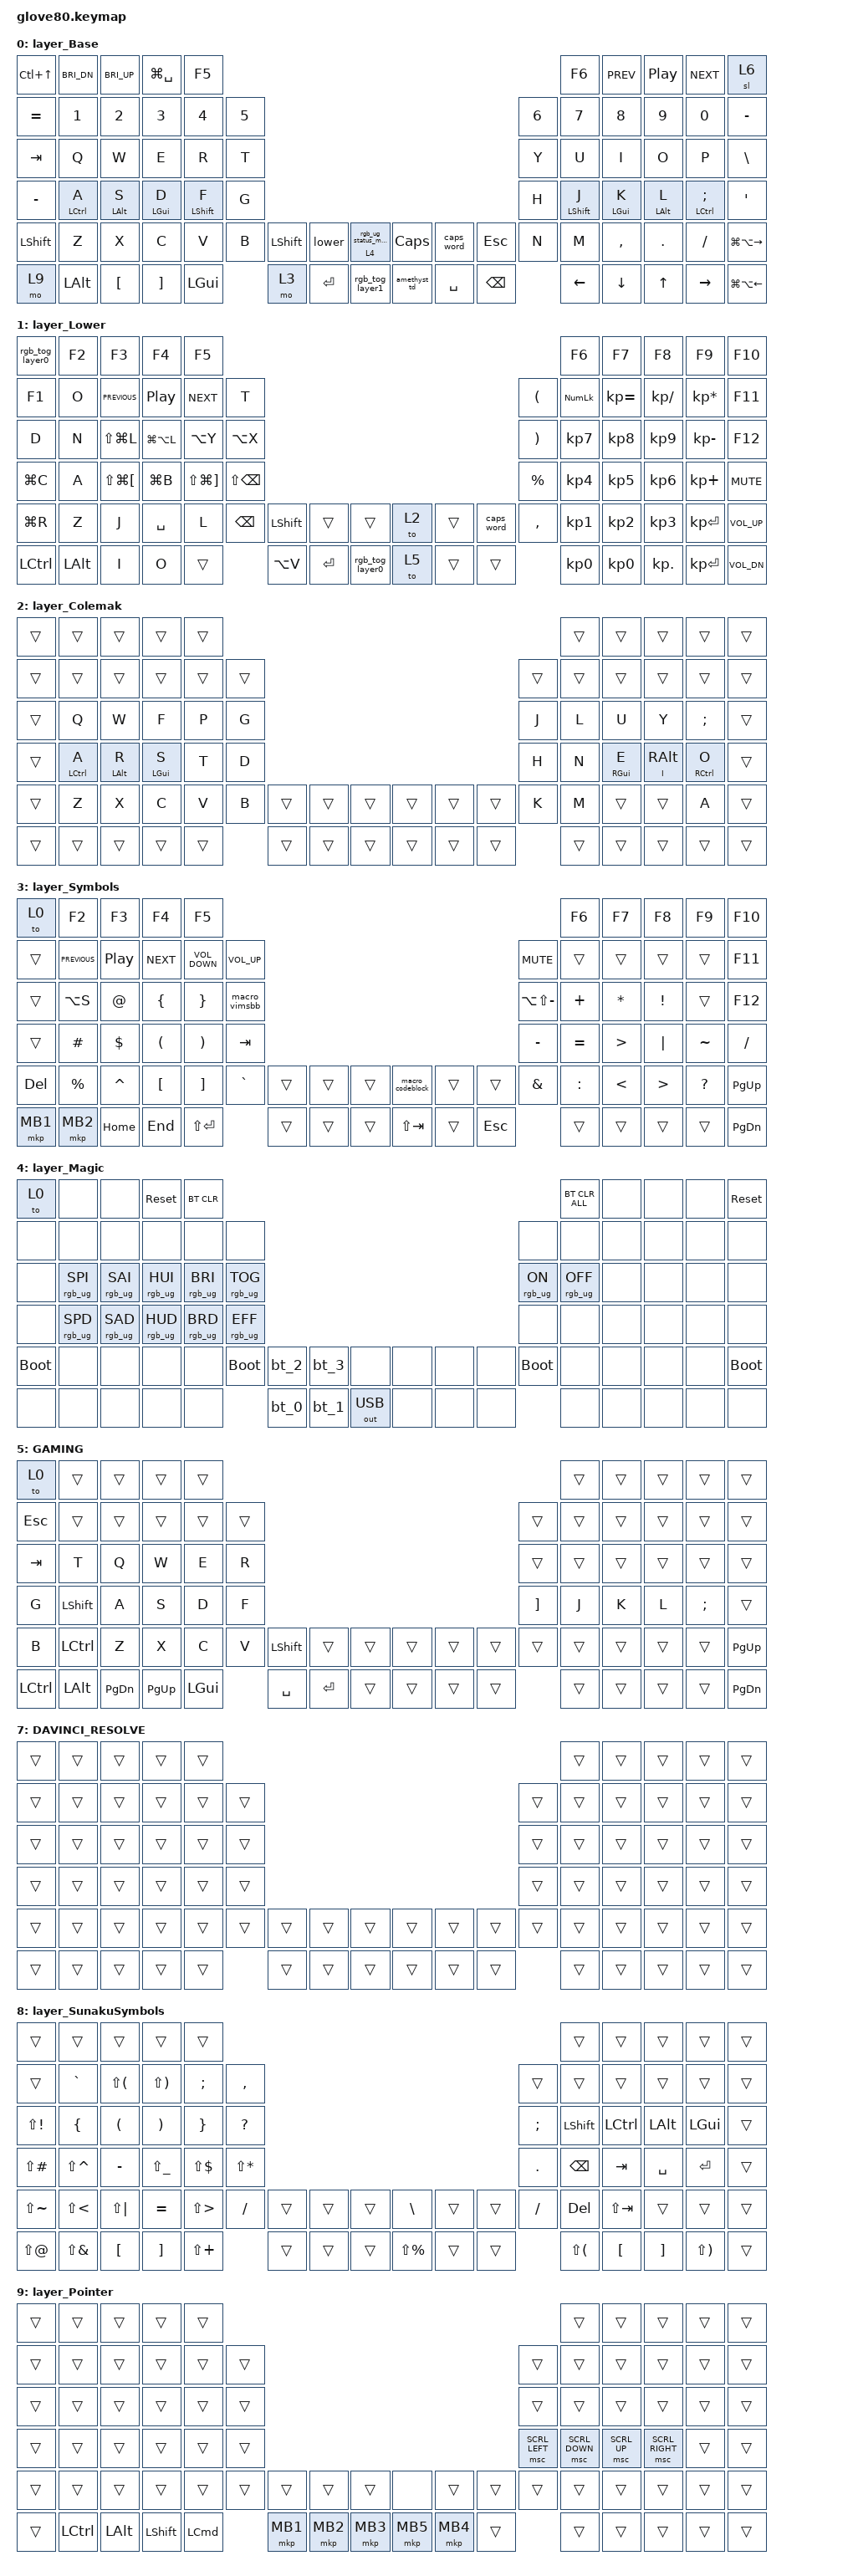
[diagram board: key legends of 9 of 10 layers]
/*
 * Copyright (c) 2020 The ZMK Contributors
 * Copyright (c) 2023 Innaworks Development Limited, trading as MoErgo
 *
 * SPDX-License-Identifier: MIT
 */
/* THIS FILE WAS GENERATED BY GLOVE80 LAYOUT EDITOR
 *
 * This file was generated automatically. You may or may not want to
 * edit it directly.
 */
/* Include all behaviour includes needed */

#include <behaviors.dtsi>
#include <dt-bindings/zmk/bt.h>
#include <dt-bindings/zmk/keys.h>
#include <dt-bindings/zmk/outputs.h>
#include <dt-bindings/zmk/pointing.h>
#include <dt-bindings/zmk/rgb.h>

/* Automatically generated layer name #define */

#define HYPER(keycode) LS(LC(LA(LG(keycode))))
#define MEH(keycode) LS(LC(LA(keycode)))

/* #define layers */

#define LAYER_Base 0
#define LAYER_Lower 1
#define LAYER_Colemak 2
#define LAYER_Symbols 3
#define LAYER_Magic 4
#define LAYER_Apps 5

/* #define for key positions */

#define POS_LH_T1 52
#define POS_LH_T2 53
#define POS_LH_T3 54
#define POS_LH_T4 69
#define POS_LH_T5 70
#define POS_LH_T6 71
#define POS_LH_C1R2 15
#define POS_LH_C1R3 27
#define POS_LH_C1R4 39
#define POS_LH_C1R5 51
#define POS_LH_C2R1 4
#define POS_LH_C2R2 14
#define POS_LH_C2R3 26
#define POS_LH_C2R4 38
#define POS_LH_C2R5 50
#define POS_LH_C2R6 68
#define POS_LH_C3R1 3
#define POS_LH_C3R2 13
#define POS_LH_C3R3 25
#define POS_LH_C3R4 37
#define POS_LH_C3R5 49
#define POS_LH_C3R6 67
#define POS_LH_C4R1 2
#define POS_LH_C4R2 12
#define POS_LH_C4R3 24
#define POS_LH_C4R4 36
#define POS_LH_C4R5 48
#define POS_LH_C4R6 66
#define POS_LH_C5R1 1
#define POS_LH_C5R2 11
#define POS_LH_C5R3 23
#define POS_LH_C5R4 35
#define POS_LH_C5R5 47
#define POS_LH_C5R6 65
#define POS_LH_C6R1 0
#define POS_LH_C6R2 10
#define POS_LH_C6R3 22
#define POS_LH_C6R4 34
#define POS_LH_C6R5 46
#define POS_LH_C6R6 64
#define POS_RH_T1 57
#define POS_RH_T2 56
#define POS_RH_T3 55
#define POS_RH_T4 74
#define POS_RH_T5 73
#define POS_RH_T6 72
#define POS_RH_C1R2 16
#define POS_RH_C1R3 28
#define POS_RH_C1R4 40
#define POS_RH_C1R5 58
#define POS_RH_C2R1 5
#define POS_RH_C2R2 17
#define POS_RH_C2R3 29
#define POS_RH_C2R4 41
#define POS_RH_C2R5 59
#define POS_RH_C2R6 75
#define POS_RH_C3R1 6
#define POS_RH_C3R2 18
#define POS_RH_C3R3 30
#define POS_RH_C3R4 42
#define POS_RH_C3R5 60
#define POS_RH_C3R6 76
#define POS_RH_C4R1 7
#define POS_RH_C4R2 19
#define POS_RH_C4R3 31
#define POS_RH_C4R4 43
#define POS_RH_C4R5 61
#define POS_RH_C4R6 77
#define POS_RH_C5R1 8
#define POS_RH_C5R2 20
#define POS_RH_C5R3 32
#define POS_RH_C5R4 44
#define POS_RH_C5R5 62
#define POS_RH_C5R6 78
#define POS_RH_C6R1 9
#define POS_RH_C6R2 21
#define POS_RH_C6R3 33
#define POS_RH_C6R4 45
#define POS_RH_C6R5 63
#define POS_RH_C6R6 79

// NOTE: I removed "C" (POS_LH_C3R4) and "D" (POS_LH_C3R5) from `KEYS_LEFT` so I can still do one-handed CTRL-C and CTRL-D

#define KEYS_LEFT POS_LH_C1R2 POS_LH_C1R3 POS_LH_C1R4 POS_LH_C1R5 POS_LH_C2R1 POS_LH_C2R2 POS_LH_C2R3 POS_LH_C2R4 POS_LH_C2R5 POS_LH_C2R6 POS_LH_C3R1 POS_LH_C3R2 POS_LH_C3R3 POS_LH_C3R6 POS_LH_C4R1 POS_LH_C4R2 POS_LH_C4R3 POS_LH_C4R4 POS_LH_C4R5 POS_LH_C4R6 POS_LH_C5R1 POS_LH_C5R2 POS_LH_C5R3 POS_LH_C5R4 POS_LH_C5R5 POS_LH_C5R6 POS_LH_C6R1 POS_LH_C6R2 POS_LH_C6R3 POS_LH_C6R4 POS_LH_C6R5 POS_LH_C6R6
#define KEYS_RIGHT POS_RH_C1R2 POS_RH_C1R3 POS_RH_C1R4 POS_RH_C1R5 POS_RH_C2R1 POS_RH_C2R2 POS_RH_C2R3 POS_RH_C2R4 POS_RH_C2R5 POS_RH_C2R6 POS_RH_C3R1 POS_RH_C3R2 POS_RH_C3R3 POS_RH_C3R4 POS_RH_C3R5 POS_RH_C3R6 POS_RH_C4R1 POS_RH_C4R2 POS_RH_C4R3 POS_RH_C4R4 POS_RH_C4R5 POS_RH_C4R6 POS_RH_C5R1 POS_RH_C5R2 POS_RH_C5R3 POS_RH_C5R4 POS_RH_C5R5 POS_RH_C5R6 POS_RH_C6R1 POS_RH_C6R2 POS_RH_C6R3 POS_RH_C6R4 POS_RH_C6R5 POS_RH_C6R6
#define THUMBS POS_RH_T1 POS_RH_T2 POS_RH_T3 POS_RH_T4 POS_RH_T5 POS_RH_T6 POS_LH_T1 POS_LH_T2 POS_LH_T3 POS_LH_T4 POS_LH_T5 POS_LH_T6

/ {
    /* Glove80 system behavior & macros */

    behaviors {
        // For the "layer" key, it'd nice to be able to use it as either a shift or a toggle.
        // Configure it as a tap dance, so the first tap (or hold) is a &mo and the second tap is a &to

        lower: lower {
            compatible = "zmk,behavior-tap-dance";
            label = "LAYER_TAP_DANCE";
            #binding-cells = <0>;
            tapping-term-ms = <200>;
            bindings = <&mo 1>, <&to 1>;
        };

        rpi: require_prior_idle {
            compatible = "zmk,behavior-hold-tap";
            label = "REQUIRE_PRIOR_IDLE";
            #binding-cells = <2>;
            flavor = "tap-preferred";
            tapping-term-ms = <175>;
            quick-tap-ms = <150>;
            require-prior-idle-ms = <125>;
            bindings = <&kp>, <&kp>;
        };

        hml: hold_tap_left {
            compatible = "zmk,behavior-hold-tap";
            label = "HRM_HOLD_TAP_LEFT";
            flavor = "balanced";
            tapping-term-ms = <280>;
            quick-tap-ms = <175>;
            require-prior-idle-ms = <150>;
            #binding-cells = <2>;
            bindings = <&kp>, <&kp>;

            hold-trigger-key-positions = <KEYS_RIGHT THUMBS>;
            hold-trigger-on-release;
        };

        hmr: hold_tap_right {
            compatible = "zmk,behavior-hold-tap";
            label = "HRM_HOLD_TAP_RIGHT";
            flavor = "balanced";
            tapping-term-ms = <280>;
            quick-tap-ms = <175>;
            require-prior-idle-ms = <150>;
            #binding-cells = <2>;
            bindings = <&kp>, <&kp>;

            hold-trigger-key-positions = <KEYS_LEFT THUMBS>;
            hold-trigger-on-release;
        };

        qt: quick_tap {
            compatible = "zmk,behavior-hold-tap";
            label = "QUICK_TAP";
            flavor = "balanced";
            tapping-term-ms = <200>;
            quick-tap-ms = <175>;
            require-prior-idle-ms = <150>;
            #binding-cells = <2>;
            bindings = <&kp>, <&kp>;

            hold-trigger-on-release;
        };

        amethyst_td: amethyst_td {
            compatible = "zmk,behavior-tap-dance";
            label = "AMETHYST_TD";
            #binding-cells = <0>;
            tapping-term-ms = <200>;
            bindings =
                <&kp LS(LEFT_ALT)>,
                <&kp LS(LA(LCTRL))>,
                <&kp LS(LA(LC(Z)))>;
        };
    };
};

/ {
    macros {
        rgb_ug_status_macro: rgb_ug_status_macro {
            label = "RGB_UG_STATUS";
            compatible = "zmk,behavior-macro";
            #binding-cells = <0>;
            bindings = <&rgb_ug RGB_STATUS>;
        };

        bt_0: bt_0 {
            label = "BT_0";
            compatible = "zmk,behavior-macro";
            #binding-cells = <0>;
            bindings = <&out OUT_BLE &bt BT_SEL 0>;
        };

        bt_1: bt_1 {
            label = "BT_1";
            compatible = "zmk,behavior-macro";
            #binding-cells = <0>;
            bindings = <&out OUT_BLE &bt BT_SEL 1>;
        };

        bt_2: bt_2 {
            label = "BT_2";
            compatible = "zmk,behavior-macro";
            #binding-cells = <0>;
            bindings = <&out OUT_BLE &bt BT_SEL 2>;
        };

        bt_3: bt_3 {
            label = "BT_3";
            compatible = "zmk,behavior-macro";
            #binding-cells = <0>;
            bindings = <&out OUT_BLE &bt BT_SEL 3>;
        };

        rgb_tog_layer0: rgb_layer0 {
            compatible = "zmk,behavior-macro";
            #binding-cells = <0>;
            bindings =
                <&macro_tap>,
                <&to 0>,
                <&macro_tap>,
                <&rgb_ug RGB_COLOR_HSB(230,95,23)>;

            label = "RGB_LAYER0";
        };

        rgb_tog_layer1: tog_layer1_rgb {
            compatible = "zmk,behavior-macro";
            #binding-cells = <0>;
            bindings =
                <&macro_tap>,
                <&to 1>,
                <&macro_tap>,
                <&rgb_ug RGB_COLOR_HSB(126,100,33)>;

            label = "TOG_LAYER1_RGB";
        };

        rgb_mo_layer6: rgb_mo_layer6 {
            compatible = "zmk,behavior-macro";
            #binding-cells = <0>;
            bindings =
                <&macro_press>,
                <&mo 5>,
                <&macro_tap>,
                <&rgb_ug RGB_COLOR_HSB(233,99,30)>,
                <&macro_pause_for_release>,
                <&macro_release>,
                <&mo 5>,
                <&macro_tap>,
                <&rgb_ug RGB_COLOR_HSB(131,100,30)>;

            label = "RGB_MO_LAYER6";
        };
    };
};

/ {
    magic: magic {
        compatible = "zmk,behavior-hold-tap";
        label = "MAGIC_HOLD_TAP";
        #binding-cells = <2>;
        flavor = "tap-preferred";
        tapping-term-ms = <200>;
        bindings = <&mo>, <&rgb_ug_status_macro>;
    };
};

/* Custom Defined Behaviors */

/ {
    macro_codeblock: macro_codeblock {
        compatible = "zmk,behavior-macro";
        label = "macro_codeblock";
        #binding-cells = <0>;
        wait-ms = <30>;
        tap-ms = <40>;
        bindings = <&kp GRAVE &kp GRAVE &kp GRAVE &kp LS(ENTER) &kp GRAVE &kp GRAVE &kp GRAVE &kp UP &kp LS(ENTER)>;
    };

    macro_vimsbb: macro_vim_select_between_brackets {
        compatible = "zmk,behavior-macro";
        label = "macro_vimsbb";
        #binding-cells = <0>;
        wait-ms = <30>;
        tap-ms = <40>;
        bindings = <&kp LS(N4) &kp LS(V) &kp PERCENT &kp LS(N4)>;
    };

    macro_tmux_vim: macro_tmux_vim {
        compatible = "zmk,behavior-macro";
        label = "macro_tmux_vim";
        #binding-cells = <0>;
        wait-ms = <30>;
        tap-ms = <40>;
        bindings = <&kp LG(S) &kp LBKT>;
    };

    mo_rgb: mo_rgb {
        label = "LAYER_MOD";
        compatible = "zmk,behavior-macro";
        wait-ms = <0>;
        tap-ms = <0>;
        #binding-cells = <0>;
        bindings =
            <&macro_press>,
            <&mo 7>,
            <&macro_tap>,
            <&rgb_ug RGB_COLOR_HSB(128,100,100)>,
            <&macro_pause_for_release>,
            <&macro_release>,
            <&mo 7>,
            <&macro_tap>,
            <&rgb_ug RGB_COLOR_HSB(300,100,50)>;
    };
};

/ {
    behaviors {
    };

    combos {
        compatible = "zmk,combos";

        toggle_layer1 {
            bindings = <&rgb_tog_layer1>;
            key-positions = <66 67 68>;
            layers = <0>;
            require-prior-idle-ms = <150>;
        };

        switch-tab-left {
            bindings = <&kp LG(LA(LEFT))>;
            key-positions = <75 76>;
            layers = <0>;
            require-prior-idle-ms = <150>;
        };

        switch-tab-right {
            bindings = <&kp LG(LA(RIGHT))>;
            key-positions = <76 77>;
            layers = <0>;
            require-prior-idle-ms = <150>;
        };

        to_base {
            bindings = <&rgb_tog_layer0>;
            key-positions = <66 67 68>;
            layers = <1>;
            require-prior-idle-ms = <150>;
        };

        magic_layer {
            bindings = <&magic 7 0>;
            key-positions = <68 65>;
            layers = <0 1>;
            require-prior-idle-ms = <200>;
        };
    };

    keymap {
        compatible = "zmk,keymap";

        layer_Base {
            bindings = <
&kp LC(UP)      &kp C_BRI_DN  &kp C_BRI_UP      &kp LG(SPACE)      &kp F5                                                                                                                  &kp F6             &kp C_PREV   &kp C_PP         &kp C_NEXT           &sl 6
&kp EQUAL       &kp N1        &kp N2            &kp N3             &kp N4             &kp N5                                                                                       &kp N6  &kp N7             &kp N8       &kp N9           &kp N0               &kp MINUS
&kp TAB         &kp Q         &kp W             &kp E              &kp R              &kp T                                                                                        &kp Y   &kp U              &kp I        &kp O            &kp P                &kp BSLH
&kp MINUS       &qt LCTRL A   &hml LEFT_ALT S   &hml LEFT_GUI D    &hml LEFT_SHIFT F  &kp G                                                                                        &kp H   &hmr LEFT_SHIFT J  &hmr LGUI K  &hmr LEFT_ALT L  &qt LCTRL SEMICOLON  &kp SQT
&kp LEFT_SHIFT  &kp Z         &kp X             &kp C              &kp V              &kp B   &kp LEFT_SHIFT  &lower     &magic 4 0       &kp CAPSLOCK  &caps_word  &kp ESCAPE     &kp N   &kp M              &kp COMMA    &kp DOT          &kp FSLH             &kp LG(LA(RIGHT))
&mo 9           &kp LEFT_ALT  &kp LEFT_BRACKET  &kp RIGHT_BRACKET  &kp LGUI                   &mo 3           &kp ENTER  &rgb_tog_layer1  &amethyst_td  &kp SPACE   &kp BACKSPACE          &kp LEFT           &kp DOWN     &kp UP           &kp RIGHT            &kp LG(LA(LEFT))
            >;
        };

        layer_Lower {
            bindings = <
&rgb_tog_layer0  &kp F2    &kp F3                    &kp F4            &kp F5                                                                                                                                      &kp F6      &kp F7        &kp F8        &kp F9           &kp F10
&kp F1           &kp O     &kp C_PREVIOUS            &kp C_PLAY_PAUSE  &kp C_NEXT                 &kp T                                                                                     &kp LEFT_PARENTHESIS   &kp KP_NUM  &kp KP_EQUAL  &kp KP_SLASH  &kp KP_MULTIPLY  &kp F11
&kp D            &kp N     &kp LS(LG(L))             &kp LG(LA(L))     &kp LA(Y)                  &kp LA(X)                                                                                 &kp RIGHT_PARENTHESIS  &kp KP_N7   &kp KP_N8     &kp KP_N9     &kp KP_MINUS     &kp F12
&kp LG(C)        &kp A     &kp LS(LG(LEFT_BRACKET))  &kp LG(B)         &kp LS(LG(RIGHT_BRACKET))  &kp LS(BACKSPACE)                                                                         &kp PERCENT            &kp KP_N4   &kp KP_N5     &kp KP_N6     &kp KP_PLUS      &kp K_MUTE
&kp LG(R)        &kp Z     &kp J                     &kp SPACE         &kp L                      &kp BACKSPACE      &kp LEFT_SHIFT  &trans     &trans           &to 2  &trans  &caps_word  &kp COMMA              &kp KP_N1   &kp KP_N2     &kp KP_N3     &kp KP_ENTER     &kp C_VOLUME_UP
&kp LCTRL        &kp LALT  &kp I                     &kp O             &trans                                        &kp LA(V)       &kp ENTER  &rgb_tog_layer0  &to 5  &trans  &trans                             &kp KP_N0   &kp KP_N0     &kp KP_DOT    &kp KP_ENTER     &kp C_VOL_DN
            >;
        };

        layer_Colemak {
            bindings = <
&trans  &trans       &trans           &trans           &trans                                                                  &trans  &trans            &trans            &trans       &trans
&trans  &trans       &trans           &trans           &trans  &trans                                                  &trans  &trans  &trans            &trans            &trans       &trans
&trans  &kp Q        &kp W            &kp F            &kp P   &kp G                                                   &kp J   &kp L   &kp U             &kp Y             &kp SEMI     &trans
&trans  &qt LCTRL A  &hml LEFT_ALT R  &hml LEFT_GUI S  &kp T   &kp D                                                   &kp H   &kp N   &hmr RIGHT_GUI E  &hmr I RIGHT_ALT  &qt RCTRL O  &trans
&trans  &kp Z        &kp X            &kp C            &kp V   &kp B   &trans  &trans  &trans  &trans  &trans  &trans  &kp K   &kp M   &trans            &trans            &kp A        &trans
&trans  &trans       &trans           &trans           &trans          &trans  &trans  &trans  &trans  &trans  &trans          &trans  &trans            &trans            &trans       &trans
            >;
        };

        layer_Symbols {
            bindings = <
&to 0       &kp F2          &kp F3            &kp F4      &kp F5                                                                                                            &kp F6     &kp F7            &kp F8            &kp F9        &kp F10
&trans      &kp C_PREVIOUS  &kp C_PLAY_PAUSE  &kp C_NEXT  &kp C_VOLUME_DOWN  &kp C_VOLUME_UP                                                             &kp C_MUTE         &trans     &trans            &trans            &trans        &kp F11
&trans      &kp LA(S)       &kp AT_SIGN       &kp LBRC    &kp RBRC           &macro_vimsbb                                                               &kp LA(LS(MINUS))  &kp PLUS   &kp ASTERISK      &kp EXCLAMATION   &trans        &kp F12
&trans      &kp POUND       &kp DOLLAR        &kp LPAR    &kp RPAR           &kp TAB                                                                     &kp MINUS          &kp EQUAL  &kp GREATER_THAN  &kp PIPE          &kp TILDE     &kp FSLH
&kp DELETE  &kp PERCENT     &kp CARET         &kp LBKT    &kp RBKT           &kp GRAVE        &trans  &trans  &trans  &macro_codeblock  &trans  &trans   &kp AMPERSAND      &kp COLON  &kp LESS_THAN     &kp GREATER_THAN  &kp QUESTION  &kp PAGE_UP
&mkp MB1    &mkp MB2        &kp HOME          &kp END     &kp LS(ENTER)                       &trans  &trans  &trans  &kp LS(TAB)       &trans  &kp ESC                     &trans     &trans            &trans            &trans        &kp PG_DN
            >;
        };

        layer_Magic {
            bindings = <
&to 0        &none            &none            &sys_reset       &bt BT_CLR                                                                                         &bt BT_CLR_ALL   &none  &none  &none  &sys_reset
&none        &none            &none            &none            &none            &none                                                             &none           &none            &none  &none  &none  &none
&none        &rgb_ug RGB_SPI  &rgb_ug RGB_SAI  &rgb_ug RGB_HUI  &rgb_ug RGB_BRI  &rgb_ug RGB_TOG                                                   &rgb_ug RGB_ON  &rgb_ug RGB_OFF  &none  &none  &none  &none
&none        &rgb_ug RGB_SPD  &rgb_ug RGB_SAD  &rgb_ug RGB_HUD  &rgb_ug RGB_BRD  &rgb_ug RGB_EFF                                                   &none           &none            &none  &none  &none  &none
&bootloader  &none            &none            &none            &none            &bootloader      &bt_2  &bt_3  &none         &none  &none  &none  &bootloader     &none            &none  &none  &none  &bootloader
&none        &none            &none            &none            &none                             &bt_0  &bt_1  &out OUT_USB  &none  &none  &none                  &none            &none  &none  &none  &none
            >;
        };

        layer_Gaming {
            bindings = <
&to 0       &trans          &trans     &trans     &trans                                                                                     &trans  &trans  &trans  &trans    &trans
&kp ESCAPE  &trans          &trans     &trans     &trans        &trans                                                             &trans    &trans  &trans  &trans  &trans    &trans
&kp TAB     &kp T           &kp Q      &kp W      &kp E         &kp R                                                              &trans    &trans  &trans  &trans  &trans    &trans
&kp G       &kp LEFT_SHIFT  &kp A      &kp S      &kp D         &kp F                                                              &kp RBKT  &kp J   &kp K   &kp L   &kp SEMI  &trans
&kp B       &kp LCTRL       &kp Z      &kp X      &kp C         &kp V   &kp LEFT_SHIFT  &trans     &trans  &trans  &trans  &trans  &trans    &trans  &trans  &trans  &trans    &kp PG_UP
&kp LCTRL   &kp LEFT_ALT    &kp PG_DN  &kp PG_UP  &kp LEFT_GUI          &kp SPACE       &kp ENTER  &trans  &trans  &trans  &trans            &trans  &trans  &trans  &trans    &kp PG_DN
            >;

            label = "GAMING";
        };

        layer_Apps {
            bindings = <
&to 0   &kp F2                 &kp F3                 &kp F4                 &kp F5                                                                                                         &kp F6                 &kp F7                 &kp F8                 &kp F9                 &kp F10
&kp F1  &none                  &none                  &none                  &none                  &none                                                            &none                  &none                  &none                  &none                  &none                  &kp F11
&none   &kp LG(LS(LC(LA(Q))))  &kp LG(LS(LC(LA(W))))  &kp LG(LS(LC(LA(E))))  &kp LG(LS(LC(LA(R))))  &kp LG(LS(LC(LA(T))))                                            &kp LG(LS(LC(LA(Y))))  &kp LG(LS(LC(LA(U))))  &kp LG(LS(LC(LA(I))))  &kp LG(LS(LC(LA(O))))  &kp LG(LS(LC(LA(P))))  &kp F12
&none   &kp LG(LS(LC(LA(A))))  &kp LG(LS(LC(LA(S))))  &kp LG(LS(LC(LA(D))))  &kp LG(LS(LC(LA(F))))  &kp LG(LS(LC(LA(G))))                                            &kp LG(LS(LC(LA(H))))  &kp LG(LS(LC(LA(J))))  &kp LG(LS(LC(LA(K))))  &kp LG(LS(LC(LA(L))))  &none                  &none
&none   &kp LG(LS(LC(LA(Z))))  &kp LG(LS(LC(LA(X))))  &kp LG(LS(LC(LA(C))))  &kp LG(LS(LC(LA(V))))  &kp LG(LS(LC(LA(B))))  &none  &none  &none  &none  &none  &none  &kp LG(LS(LC(LA(N))))  &kp LG(LS(LC(LA(M))))  &none                  &none                  &none                  &none
&none   &none                  &none                  &none                  &none                                         &none  &none  &none  &none  &none  &none                         &none                  &none                  &none                  &none                  &to 5
            >;
        };

        layer_DavinciResolve {
            bindings = <
&trans  &trans  &trans  &trans  &trans                                                                  &trans  &trans  &trans  &trans  &trans
&trans  &trans  &trans  &trans  &trans  &trans                                                  &trans  &trans  &trans  &trans  &trans  &trans
&trans  &trans  &trans  &trans  &trans  &trans                                                  &trans  &trans  &trans  &trans  &trans  &trans
&trans  &trans  &trans  &trans  &trans  &trans                                                  &trans  &trans  &trans  &trans  &trans  &trans
&trans  &trans  &trans  &trans  &trans  &trans  &trans  &trans  &trans  &trans  &trans  &trans  &trans  &trans  &trans  &trans  &trans  &trans
&trans  &trans  &trans  &trans  &trans          &trans  &trans  &trans  &trans  &trans  &trans          &trans  &trans  &trans  &trans  &trans
            >;

            label = "DAVINCI_RESOLVE";
        };

        layer_SunakuSymbols {
            bindings = <
&trans         &trans          &trans                &trans                 &trans                                                                                          &trans          &trans       &trans        &trans        &trans
&trans         &kp GRAVE       &kp LS(LPAR)          &kp LS(RPAR)           &kp SEMI         &kp COMMA                                                            &trans    &trans          &trans       &trans        &trans        &trans
&kp LS(EXCL)   &kp LEFT_BRACE  &kp LEFT_PARENTHESIS  &kp RIGHT_PARENTHESIS  &kp RIGHT_BRACE  &kp QUESTION                                                         &kp SEMI  &kp LEFT_SHIFT  &kp LCTRL    &kp LEFT_ALT  &kp LEFT_GUI  &trans
&kp LS(POUND)  &kp LS(CARET)   &kp MINUS             &kp LS(UNDER)          &kp LS(DLLR)     &kp LS(STAR)                                                         &kp DOT   &kp BSPC        &kp TAB      &kp SPACE     &kp RET       &trans
&kp LS(TILDE)  &kp LS(LT)      &kp LS(PIPE)          &kp EQUAL              &kp LS(GT)       &kp FSLH      &trans  &trans  &trans  &kp BSLH       &trans  &trans  &kp FSLH  &kp DEL         &kp LS(TAB)  &trans        &trans        &trans
&kp LS(AT)     &kp LS(AMPS)    &kp LBKT              &kp RBKT               &kp LS(PLUS)                   &trans  &trans  &trans  &kp LS(PRCNT)  &trans  &trans            &kp LS(LPAR)    &kp LBKT     &kp RBKT      &kp LS(RPAR)  &trans
            >;
        };

        layer_Pointer {
            bindings = <
&trans  &trans     &trans        &trans          &trans                                                                                              &trans          &trans        &trans           &trans  &trans
&trans  &trans     &trans        &trans          &trans            &trans                                                            &trans          &trans          &trans        &trans           &trans  &trans
&trans  &trans     &trans        &trans          &trans            &trans                                                            &trans          &trans          &trans        &trans           &trans  &trans
&trans  &trans     &trans        &trans          &trans            &trans                                                            &msc SCRL_LEFT  &msc SCRL_DOWN  &msc SCRL_UP  &msc SCRL_RIGHT  &trans  &trans
&trans  &trans     &trans        &trans          &trans            &trans  &trans    &trans    &trans    &none     &trans    &trans  &trans          &trans          &trans        &trans           &trans  &trans
&trans  &kp LCTRL  &kp LEFT_ALT  &kp LEFT_SHIFT  &kp LEFT_COMMAND          &mkp MB1  &mkp MB2  &mkp MB3  &mkp MB5  &mkp MB4  &trans                  &trans          &trans        &trans           &trans  &trans
            >;
        };
    };
};
